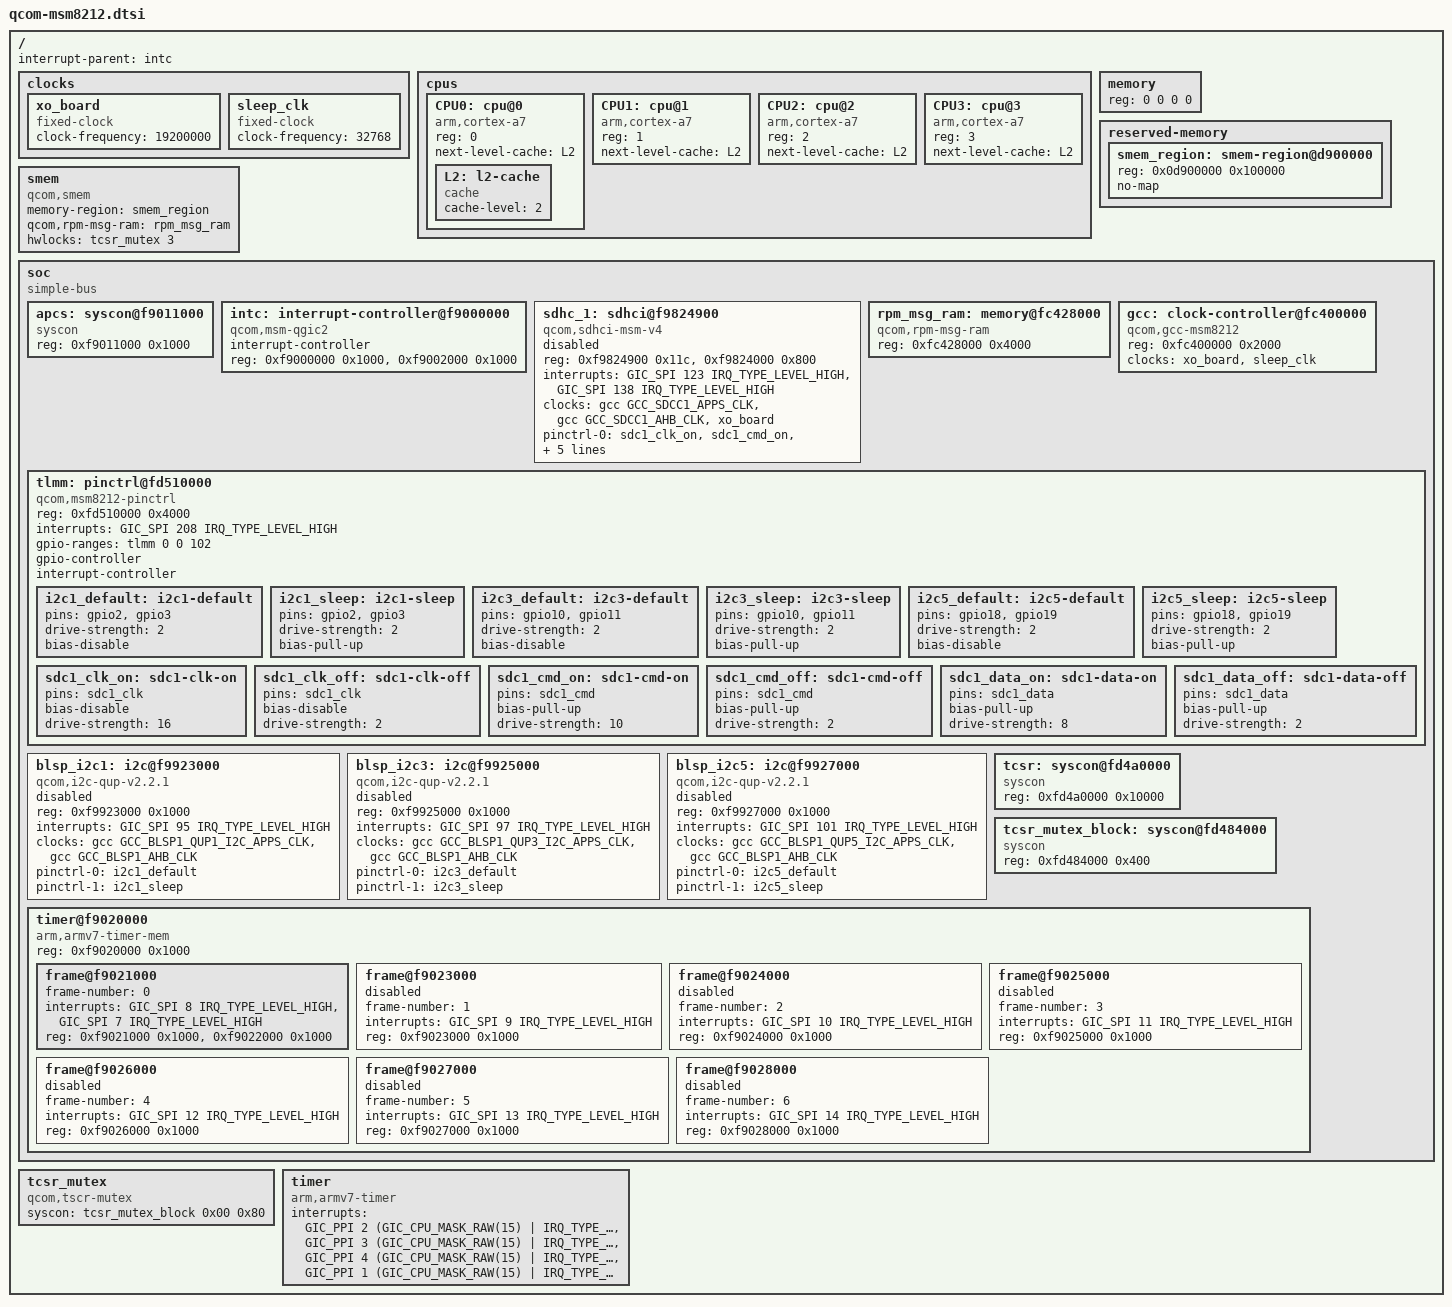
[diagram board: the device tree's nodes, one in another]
// SPDX-License-Identifier: BSD-3-Clause
/*
 * Copyright (c) 2021, Ivaylo Ivanov <ivo.ivanov@null.net>
 * Copyright (c) 2021, Konrad Dybcio <konrad.dybcio@somainline.org>
 */
/dts-v1/;

#include <dt-bindings/clock/qcom,gcc-msm8974.h>
#include <dt-bindings/reset/qcom,gcc-msm8974.h>
#include <dt-bindings/clock/qcom,rpmcc.h>
#include <dt-bindings/gpio/gpio.h>
#include <dt-bindings/interrupt-controller/arm-gic.h>



/ {
	interrupt-parent = <&intc>;

	#address-cells = <1>;
	#size-cells = <1>;

	clocks {
		xo_board: xo_board {
			compatible = "fixed-clock";
			#clock-cells = <0>;
			clock-frequency = <19200000>;
		};

		sleep_clk: sleep_clk {
			compatible = "fixed-clock";
			#clock-cells = <0>;
			clock-frequency = <32768>;
		};
	};

	cpus {
		#address-cells = <1>;
		#size-cells = <0>;

		CPU0: cpu@0 {
			compatible = "arm,cortex-a7";
			device_type = "cpu";
			reg = <0>;
			next-level-cache = <&L2>;

			L2: l2-cache {
				compatible = "cache";
				cache-level = <2>;
			};
		};

		CPU1: cpu@1 {
			compatible = "arm,cortex-a7";
			device_type = "cpu";
			reg = <1>;
			next-level-cache = <&L2>;
		};

		CPU2: cpu@2 {
			compatible = "arm,cortex-a7";
			device_type = "cpu";
			reg = <2>;
			next-level-cache = <&L2>;
		};

		CPU3: cpu@3 {
			compatible = "arm,cortex-a7";
			device_type = "cpu";
			reg = <3>;
			next-level-cache = <&L2>;
		};
	};

	memory {
		device_type = "memory";
		/* We expect the bootloader to fill in the reg */
		reg = <0 0 0 0>;
	};

	reserved-memory {
		#address-cells = <1>;
		#size-cells = <1>;
		ranges;

		smem_region: smem-region@d900000 {
			reg = <0x0d900000 0x100000>;
			no-map;
		};
	};

	smem {
		compatible = "qcom,smem";
		memory-region = <&smem_region>;
		qcom,rpm-msg-ram = <&rpm_msg_ram>;
		hwlocks = <&tcsr_mutex 3>;
	};

	soc {
		#address-cells = <1>;
		#size-cells = <1>;
		ranges;
		compatible = "simple-bus";

		apcs: syscon@f9011000 {
			compatible = "syscon";
			reg = <0xf9011000 0x1000>;
		};

		intc: interrupt-controller@f9000000 {
			compatible = "qcom,msm-qgic2";
			interrupt-controller;
			#interrupt-cells = <3>;
			reg = <0xf9000000 0x1000>,
			      <0xf9002000 0x1000>;
		};

		sdhc_1: sdhci@f9824900 {
			compatible = "qcom,sdhci-msm-v4";
			reg = <0xf9824900 0x11c>, <0xf9824000 0x800>;
			reg-names = "hc_mem", "core_mem";

			interrupts = <GIC_SPI 123 IRQ_TYPE_LEVEL_HIGH>,
					<GIC_SPI 138 IRQ_TYPE_LEVEL_HIGH>;
			interrupt-names = "hc_irq", "pwr_irq";

			clocks = <&gcc GCC_SDCC1_APPS_CLK>,
					<&gcc GCC_SDCC1_AHB_CLK>,
					<&xo_board>;
			clock-names = "core", "iface", "xo";

			pinctrl-names = "default", "sleep";
			pinctrl-0 = <&sdc1_clk_on &sdc1_cmd_on &sdc1_data_on>;
			pinctrl-1 = <&sdc1_clk_off &sdc1_cmd_off &sdc1_data_off>;

			bus-width = <8>;
			non-removable;

			status = "disabled";
		};

		rpm_msg_ram: memory@fc428000 {
			compatible = "qcom,rpm-msg-ram";
			reg = <0xfc428000 0x4000>;
		};

		gcc: clock-controller@fc400000 {
			compatible = "qcom,gcc-msm8212";
			#clock-cells = <1>;
			#reset-cells = <1>;
			#power-domain-cells = <1>;
			reg = <0xfc400000 0x2000>;
			clocks = <&xo_board>, <&sleep_clk>;
			clock-names = "xo", "sleep";
		};

		tlmm: pinctrl@fd510000 {
			compatible = "qcom,msm8212-pinctrl";
			reg = <0xfd510000 0x4000>;
			interrupts = <GIC_SPI 208 IRQ_TYPE_LEVEL_HIGH>;
			gpio-ranges = <&tlmm 0 0 102>;
			gpio-controller;
			#gpio-cells = <2>;
			interrupt-controller;
			#interrupt-cells = <2>;

			i2c1_default: i2c1-default {
				pins = "gpio2", "gpio3";
				drive-strength = <2>;
				bias-disable;
			};

			i2c1_sleep: i2c1-sleep {
				pins = "gpio2", "gpio3";
				drive-strength = <2>;
				bias-pull-up;
			};

			i2c3_default: i2c3-default {
				pins = "gpio10", "gpio11";
				drive-strength = <2>;
				bias-disable;
			};

			i2c3_sleep: i2c3-sleep {
				pins = "gpio10", "gpio11";
				drive-strength = <2>;
				bias-pull-up;
			};

			i2c5_default: i2c5-default {
				pins = "gpio18", "gpio19";
				drive-strength = <2>;
				bias-disable;
			};

			i2c5_sleep: i2c5-sleep {
				pins = "gpio18", "gpio19";
				drive-strength = <2>;
				bias-pull-up;
			};

			sdc1_clk_on: sdc1-clk-on {
				pins = "sdc1_clk";
				bias-disable;
				drive-strength = <16>;
			};

			sdc1_clk_off: sdc1-clk-off {
				pins = "sdc1_clk";
				bias-disable;
				drive-strength = <2>;
			};

			sdc1_cmd_on: sdc1-cmd-on {
				pins = "sdc1_cmd";
				bias-pull-up;
				drive-strength = <10>;
			};

			sdc1_cmd_off: sdc1-cmd-off {
				pins = "sdc1_cmd";
				bias-pull-up;
				drive-strength = <2>;
			};

			sdc1_data_on: sdc1-data-on {
				pins = "sdc1_data";
				bias-pull-up;
				drive-strength = <8>;
			};

			sdc1_data_off: sdc1-data-off {
				pins = "sdc1_data";
				bias-pull-up;
				drive-strength = <2>;
			};
		};

		blsp_i2c1: i2c@f9923000 {
			compatible = "qcom,i2c-qup-v2.2.1";
			reg = <0xf9923000 0x1000>;
			interrupts = <GIC_SPI 95 IRQ_TYPE_LEVEL_HIGH>;

			clocks = <&gcc GCC_BLSP1_QUP1_I2C_APPS_CLK>,
					<&gcc GCC_BLSP1_AHB_CLK>;
			clock-names = "core", "iface";

			pinctrl-names = "default", "sleep";
			pinctrl-0 = <&i2c1_default>;
			pinctrl-1 = <&i2c1_sleep>;
			#address-cells = <1>;
			#size-cells = <0>;
			status = "disabled";
		};

		blsp_i2c3: i2c@f9925000 {
			compatible = "qcom,i2c-qup-v2.2.1";
			reg = <0xf9925000 0x1000>;
			interrupts = <GIC_SPI 97 IRQ_TYPE_LEVEL_HIGH>;

			clocks = <&gcc GCC_BLSP1_QUP3_I2C_APPS_CLK>,
					<&gcc GCC_BLSP1_AHB_CLK>;
			clock-names = "core", "iface";

			pinctrl-names = "default", "sleep";
			pinctrl-0 = <&i2c3_default>;
			pinctrl-1 = <&i2c3_sleep>;
			#address-cells = <1>;
			#size-cells = <0>;
			status = "disabled";
		};

		blsp_i2c5: i2c@f9927000 {
			compatible = "qcom,i2c-qup-v2.2.1";
			reg = <0xf9927000 0x1000>;
			interrupts = <GIC_SPI 101 IRQ_TYPE_LEVEL_HIGH>;

			clocks = <&gcc GCC_BLSP1_QUP5_I2C_APPS_CLK>,
					<&gcc GCC_BLSP1_AHB_CLK>;
			clock-names = "core", "iface";

			pinctrl-names = "default", "sleep";
			pinctrl-0 = <&i2c5_default>;
			pinctrl-1 = <&i2c5_sleep>;
			#address-cells = <1>;
			#size-cells = <0>;
			status = "disabled";
		};

		tcsr: syscon@fd4a0000 {
			compatible = "syscon";
			reg = <0xfd4a0000 0x10000>;
		};

		tcsr_mutex_block: syscon@fd484000 {
			compatible = "syscon";
			reg = <0xfd484000 0x400>;
		};

		timer@f9020000 {
			compatible = "arm,armv7-timer-mem";
			#address-cells = <1>;
			#size-cells = <1>;
			ranges;
			reg = <0xf9020000 0x1000>;

			frame@f9021000 {
				frame-number = <0>;
				interrupts = <GIC_SPI 8 IRQ_TYPE_LEVEL_HIGH>,
					     <GIC_SPI 7 IRQ_TYPE_LEVEL_HIGH>;
				reg = <0xf9021000 0x1000>,
				      <0xf9022000 0x1000>;
			};

			frame@f9023000 {
				frame-number = <1>;
				interrupts = <GIC_SPI 9 IRQ_TYPE_LEVEL_HIGH>;
				reg = <0xf9023000 0x1000>;
				status = "disabled";
			};

			frame@f9024000 {
				frame-number = <2>;
				interrupts = <GIC_SPI 10 IRQ_TYPE_LEVEL_HIGH>;
				reg = <0xf9024000 0x1000>;
				status = "disabled";
			};

			frame@f9025000 {
				frame-number = <3>;
				interrupts = <GIC_SPI 11 IRQ_TYPE_LEVEL_HIGH>;
				reg = <0xf9025000 0x1000>;
				status = "disabled";
			};

			frame@f9026000 {
				frame-number = <4>;
				interrupts = <GIC_SPI 12 IRQ_TYPE_LEVEL_HIGH>;
				reg = <0xf9026000 0x1000>;
				status = "disabled";
			};

			frame@f9027000 {
				frame-number = <5>;
				interrupts = <GIC_SPI 13 IRQ_TYPE_LEVEL_HIGH>;
				reg = <0xf9027000 0x1000>;
				status = "disabled";
			};

			frame@f9028000 {
				frame-number = <6>;
				interrupts = <GIC_SPI 14 IRQ_TYPE_LEVEL_HIGH>;
				reg = <0xf9028000 0x1000>;
				status = "disabled";
			};
		};
	};

	tcsr_mutex: tcsr_mutex {
		compatible = "qcom,tscr-mutex";
		syscon = <&tcsr_mutex_block 0x00 0x80>;
		#hwlock-cells = <1>;
	};

	timer {
		compatible = "arm,armv7-timer";
		interrupts = <GIC_PPI 2
				(GIC_CPU_MASK_RAW(15) | IRQ_TYPE_LEVEL_LOW)>,
			     <GIC_PPI 3
				(GIC_CPU_MASK_RAW(15) | IRQ_TYPE_LEVEL_LOW)>,
			     <GIC_PPI 4
				(GIC_CPU_MASK_RAW(15) | IRQ_TYPE_LEVEL_LOW)>,
			     <GIC_PPI 1
				(GIC_CPU_MASK_RAW(15) | IRQ_TYPE_LEVEL_LOW)>;
	};
};

